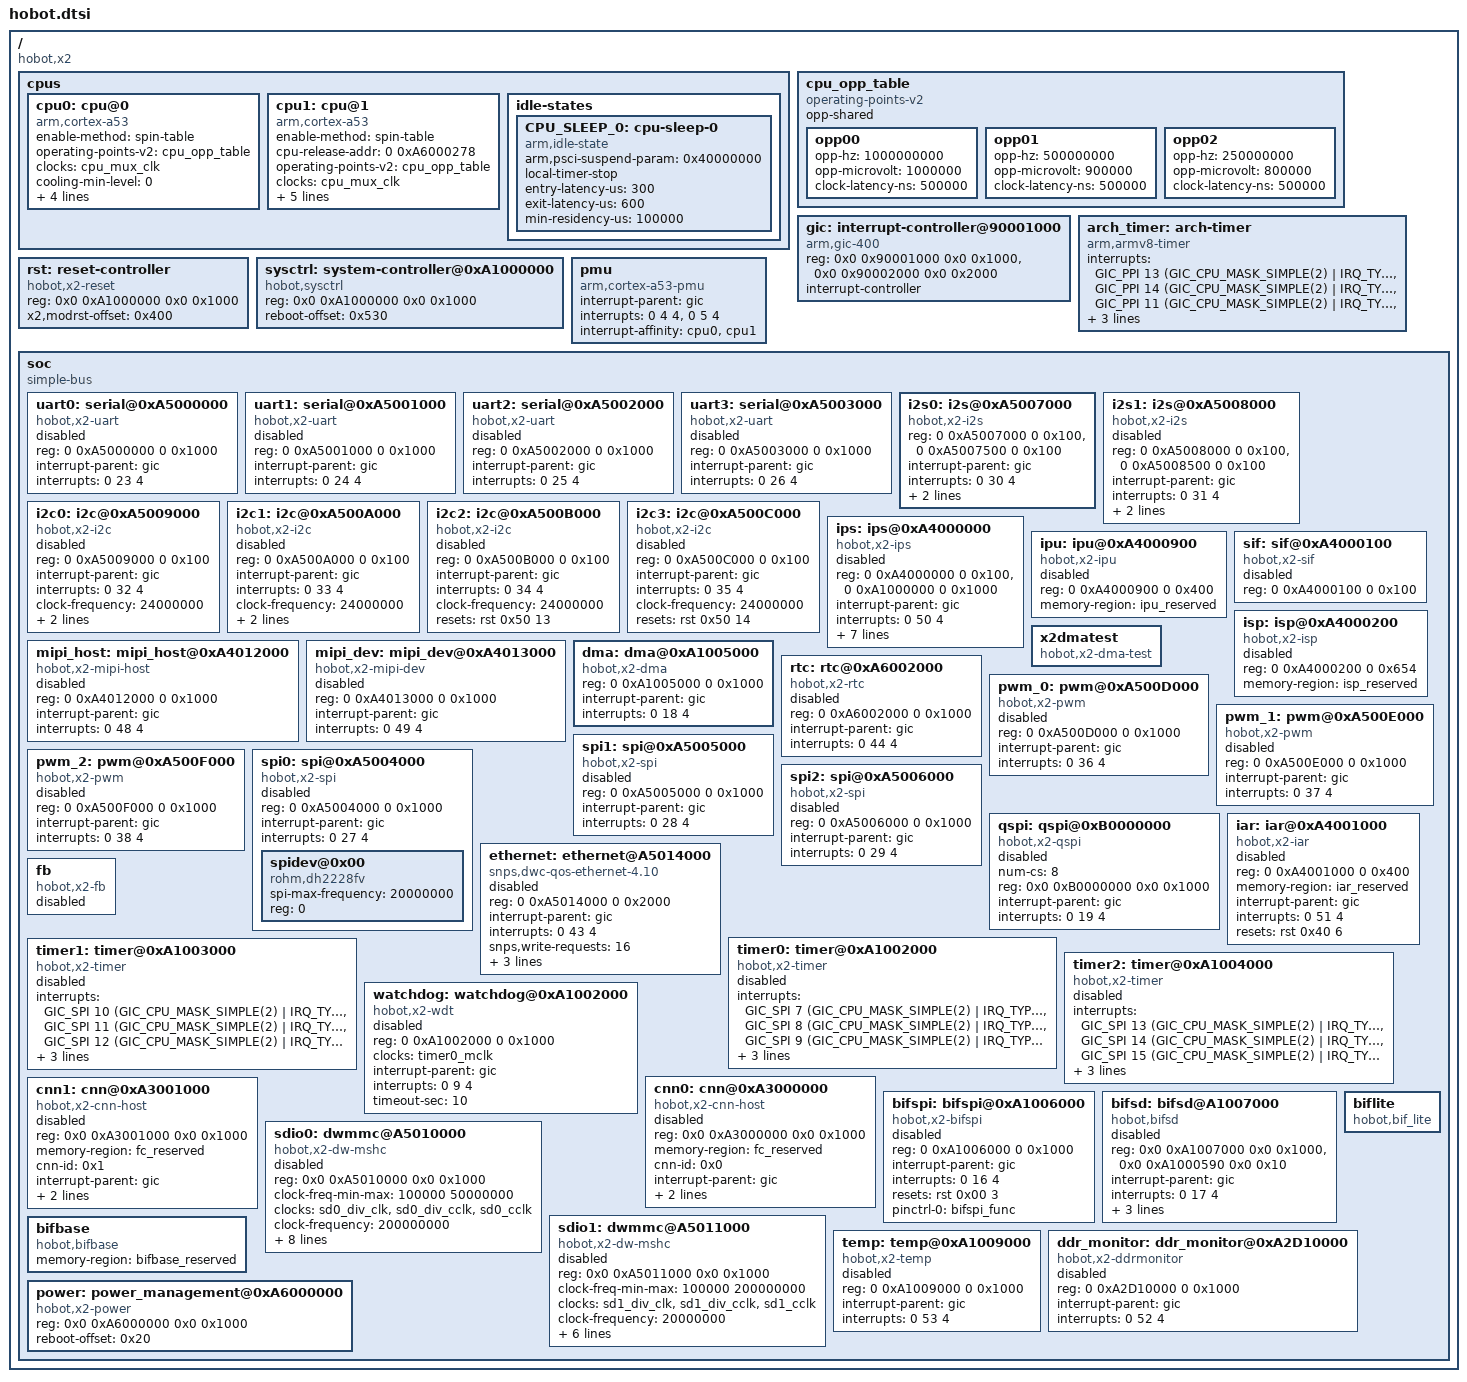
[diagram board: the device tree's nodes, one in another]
/*
 * dts file for Hobot X2 FPGA
 *
 * (C) Copyright 2018, Horizon, Inc.
 *
 *
 * This program is free software; you can redistribute it and/or
 * modify it under the terms of the GNU General Public License as
 * published by the Free Software Foundation; either version 2 of
 * the License, or (at your option) any later version.
 */

#include <dt-bindings/interrupt-controller/arm-gic.h>
#include <dt-bindings/interrupt-controller/irq.h>

 / {
	compatible = "hobot,x2";
	#address-cells = <2>;
	#size-cells = <2>;

	cpus {
		#address-cells = <1>;
		#size-cells = <0>;

		cpu0: cpu@0 {
			compatible = "arm,cortex-a53", "arm,armv8";
			device_type = "cpu";
			enable-method = "spin-table";
			operating-points-v2 = <&cpu_opp_table>;
			clocks = <&cpu_mux_clk>;
			#cooling-cells = <2>;
			cooling-min-level = <0>;
			cooling-max-level = <2>;
			dynamic-power-coefficient = <120>;
			reg = <0x0>;
			cpu-idle-states = <&CPU_SLEEP_0>;
		};

		cpu1: cpu@1 {
			compatible = "arm,cortex-a53", "arm,armv8";
			device_type = "cpu";
			enable-method = "spin-table";
			cpu-release-addr = <0 0xA6000278>;
			operating-points-v2 = <&cpu_opp_table>;
			clocks = <&cpu_mux_clk>;
			#cooling-cells = <2>;
			cooling-min-level = <0>;
			cooling-max-level = <2>;
			dynamic-power-coefficient = <120>;
			reg = <0x1>;
			cpu-idle-states = <&CPU_SLEEP_0>;
		};

		/*TODO: maybe need to change */
		idle-states {
			/*entry-method = "arm,psci";*/

			CPU_SLEEP_0: cpu-sleep-0 {
				compatible = "arm,idle-state";
				arm,psci-suspend-param = <0x40000000>;
				local-timer-stop;
				entry-latency-us = <300>;
				exit-latency-us = <600>;
				min-residency-us = <100000>;
			};
		};
	};

	/*TODO: maybe need to change or delete */
	cpu_opp_table: cpu_opp_table {
		compatible = "operating-points-v2";
		opp-shared;
		opp00 {
			opp-hz = /bits/ 64 <1000000000>;
			opp-microvolt = <1000000>;
			clock-latency-ns = <500000>;
		};
		opp01 {
			opp-hz = /bits/ 64 <500000000>;
			opp-microvolt = <900000>;
			clock-latency-ns = <500000>;
		};
		opp02 {
			opp-hz = /bits/ 64 <250000000>;
			opp-microvolt = <800000>;
			clock-latency-ns = <500000>;
		};
	};

/*
	psci {
		compatible = "arm,psci-0.2";
		method = "smc";
	};
*/

	gic: interrupt-controller@90001000 {
		compatible = "arm,gic-400", "arm,cortex-a53-gic";
		#interrupt-cells = <3>;
		reg = <0x0 0x90001000 0x0 0x1000>,		/* GICD */
			  <0x0 0x90002000 0x0 0x2000>;		/* GICC */
		interrupt-controller;
	};

	arch_timer: arch-timer{
		compatible = "arm,armv8-timer";
		interrupts = <GIC_PPI 13 (GIC_CPU_MASK_SIMPLE(2)
					 | IRQ_TYPE_LEVEL_LOW)>,
					 <GIC_PPI 14 (GIC_CPU_MASK_SIMPLE(2)
					 | IRQ_TYPE_LEVEL_LOW)>,
					 <GIC_PPI 11 (GIC_CPU_MASK_SIMPLE(2)
					 | IRQ_TYPE_LEVEL_LOW)>,
					 <GIC_PPI 10 (GIC_CPU_MASK_SIMPLE(2)
					 | IRQ_TYPE_LEVEL_LOW)>;
		interrupt-parent = <&gic>;
		clock-frequency = <20000000>;
	};

	rst: reset-controller {
		compatible = "hobot,x2-reset";
		#reset-cells = <2>;
		reg = <0x0 0xA1000000 0x0 0x1000>;
		x2,modrst-offset = <0x400>;
	};

	sysctrl: system-controller@0xA1000000 {
		compatible = "hobot,sysctrl";
		reg = <0x0 0xA1000000 0x0 0x1000>;
		reboot-offset = <0x530>;
	};

	pmu {
		compatible = "arm,cortex-a53-pmu", "arm,armv8-pmuv3";
		interrupt-parent = <&gic>;
		interrupts = <0 4 4>, <0 5 4>;
		interrupt-affinity = <&cpu0>,<&cpu1>;
	};

	soc {
		compatible = "simple-bus";
		#address-cells = <2>;
		#size-cells = <2>;
		ranges;

		uart0: serial@0xA5000000 {
			compatible = "hobot,x2-uart";
			reg = <0 0xA5000000 0 0x1000>;
			interrupt-parent = <&gic>;
			interrupts = <0 23 4>;
			status = "disabled";
		};

		uart1: serial@0xA5001000 {
			compatible = "hobot,x2-uart";
			reg = <0 0xA5001000 0 0x1000>;
			interrupt-parent = <&gic>;
			interrupts = <0 24 4>;
			status = "disabled";
		};

		uart2: serial@0xA5002000 {
			compatible = "hobot,x2-uart";
			reg = <0 0xA5002000 0 0x1000>;
			interrupt-parent = <&gic>;
			interrupts = <0 25 4>;
			status = "disabled";
		};

		uart3: serial@0xA5003000 {
			compatible = "hobot,x2-uart";
			reg = <0 0xA5003000 0 0x1000>;
			interrupt-parent = <&gic>;
			interrupts = <0 26 4>;
			status = "disabled";
		};

		i2s0: i2s@0xA5007000 {
			compatible = "hobot,x2-i2s";
			reg = <0 0xA5007000 0 0x100>,
				  <0 0xA5007500 0 0x100>;
			interrupt-parent = <&gic>;
			interrupts = <0 30 4>;
			resets = <&rst 0x50 18>;
			reset-names = "i2s";
			pinctrl-names = "default";
			pinctrl-0 = <&i2s0_func>;
		};

		i2s1: i2s@0xA5008000 {
			compatible = "hobot,x2-i2s";
			reg = <0 0xA5008000 0 0x100>,
				  <0 0xA5008500 0 0x100>;
			interrupt-parent = <&gic>;
			interrupts = <0 31 4>;
			resets = <&rst 0x50 19>;
			reset-names = "i2s";
			pinctrl-names = "default";
			pinctrl-0 = <&i2s1_func>;
			status = "disabled";
		};

		i2c0: i2c@0xA5009000 {
			compatible = "hobot,x2-i2c";
			reg = <0 0xA5009000 0 0x100>;
			interrupt-parent = <&gic>;
			interrupts = <0 32 4>;
			clock-frequency = <24000000>;
			resets = <&rst 0x50 11>;
			reset-names = "i2c0";
			status = "disabled";
			pinctrl-names = "default";
			pinctrl-0 = <&i2c0_func>;
		};

		i2c1: i2c@0xA500A000 {
			compatible = "hobot,x2-i2c";
			reg = <0 0xA500A000 0 0x100>;
			interrupt-parent = <&gic>;
			interrupts = <0 33 4>;
			clock-frequency = <24000000>;
			resets = <&rst 0x50 12>;
			reset-names = "i2c1";
			status = "disabled";
			pinctrl-names = "default";
			pinctrl-0 = <&i2c1_func>;
		};

		i2c2: i2c@0xA500B000 {
			compatible = "hobot,x2-i2c";
			reg = <0 0xA500B000 0 0x100>;
			interrupt-parent = <&gic>;
			interrupts = <0 34 4>;
			clock-frequency = <24000000>;
			resets = <&rst 0x50 13>;
			reset-names = "i2c2";
			status = "disabled";
		};

		i2c3: i2c@0xA500C000 {
			compatible = "hobot,x2-i2c";
			reg = <0 0xA500C000 0 0x100>;
			interrupt-parent = <&gic>;
			interrupts = <0 35 4>;
			clock-frequency = <24000000>;
			resets = <&rst 0x50 14>;
			reset-names = "i2c3";
			status = "disabled";
		};

		ips: ips@0xA4000000 {
			compatible = "hobot,x2-ips";
			reg = <0 0xA4000000 0 0x100>,
				  <0 0xA1000000 0  0x1000>;
			interrupt-parent = <&gic>;
			interrupts = <0 50 4>;
			status = "disabled";
			resets = <&rst 0x40 0>, <&rst 0x40 1>, <&rst 0x40 2>, <&rst 0x40 3>, <&rst 0x40 4>, <&rst 0x40 5>;
			reset-names = "mipi_ipi", "mipi_cfg", "sif", "ipu", "dvp", "bt";
			clocks = <&vio_pllmux_clk>, <&mipi_ipi_1stdiv_clk>,
				<&viopll_clk>, <&vio_div_aclk>,<&sif_div_mclk>,
				<&mipi_cfg_2nddiv_clk>,<&pym_div_mclk>,
				<&mipi_phy_ref_2nddiv_clk>,
				<&sensor_2nddiv_clk>,
				<&mipi_ipi_2nddiv_clk>,<&iar_pix_div_clk>;
			clock-names = "vio_pllmux", "ipi_div1",
				"vio_pll", "vio_aclk", "sif_mclk",
				"mipi_cfg", "pym_mclk", "mipi_phy_ref",
				"sensor_mclk", "ipi_div2", "iar_pix";
		};

		ipu: ipu@0xA4000900 {
			compatible = "hobot,x2-ipu";
			reg = <0 0xA4000900 0 0x400>;
			memory-region = <&ipu_reserved>;
			status = "disabled";
		};

		sif: sif@0xA4000100 {
			compatible = "hobot,x2-sif";
			reg = <0 0xA4000100 0 0x100>;
			status = "disabled";
		};

		isp: isp@0xA4000200 {
			compatible = "hobot,x2-isp";
			reg = <0 0xA4000200 0 0x654>;
			memory-region = <&isp_reserved>;
			status = "disabled";
		};

		mipi_host: mipi_host@0xA4012000 {
			compatible = "hobot,x2-mipi-host";
			reg = <0 0xA4012000 0 0x1000>;
			interrupt-parent = <&gic>;
			interrupts = <0 48 4>;
			status = "disabled";
		};

		mipi_dev: mipi_dev@0xA4013000 {
			compatible = "hobot,x2-mipi-dev";
			reg = <0 0xA4013000 0 0x1000>;
			interrupt-parent = <&gic>;
			interrupts = <0 49 4>;
			status = "disabled";
		};

		dma: dma@0xA1005000 {
			compatible = "hobot,x2-dma";
			reg = <0 0xA1005000 0 0x1000>;
			interrupt-parent = <&gic>;
			interrupts = <0 18 4>;
		};

		x2dmatest: x2dmatest {
			compatible = "hobot,x2-dma-test";
		};

		rtc: rtc@0xA6002000 {
			compatible = "hobot,x2-rtc";
			reg = <0 0xA6002000 0 0x1000>;
			interrupt-parent = <&gic>;
			interrupts = <0 44 4>;
			status = "disabled";
		};

		pwm_0: pwm@0xA500D000 {
			compatible = "hobot,x2-pwm";
			reg = <0 0xA500D000 0 0x1000>;
			interrupt-parent = <&gic>;
			interrupts = <0 36 4>;
			status = "disabled";
		};

		pwm_1: pwm@0xA500E000 {
			compatible = "hobot,x2-pwm";
			reg = <0 0xA500E000 0 0x1000>;
			interrupt-parent = <&gic>;
			interrupts = <0 37 4>;
			status = "disabled";
		};

		pwm_2: pwm@0xA500F000 {
			compatible = "hobot,x2-pwm";
			reg = <0 0xA500F000 0 0x1000>;
			interrupt-parent = <&gic>;
			interrupts = <0 38 4>;
			status = "disabled";
		};

		spi0: spi@0xA5004000 {
			compatible = "hobot,x2-spi";
			reg = <0 0xA5004000 0 0x1000>;
			interrupt-parent = <&gic>;
			interrupts = <0 27 4>;
			status = "disabled";
			#address-cells = <1>;
			#size-cells = <0>;
			spidev@0x00 {
				compatible = "rohm,dh2228fv";
				spi-max-frequency = <20000000>;
				reg = <0>;
			};
		};

		spi1: spi@0xA5005000 {
			compatible = "hobot,x2-spi";
			reg = <0 0xA5005000 0 0x1000>;
			interrupt-parent = <&gic>;
			interrupts = <0 28 4>;
			status = "disabled";
			#address-cells = <1>;
			#size-cells = <0>;
		};

		spi2: spi@0xA5006000 {
			compatible = "hobot,x2-spi";
			reg = <0 0xA5006000 0 0x1000>;
			interrupt-parent = <&gic>;
			interrupts = <0 29 4>;
			status = "disabled";
			#address-cells = <1>;
			#size-cells = <0>;
		};

		qspi: qspi@0xB0000000 {
			compatible = "hobot,x2-qspi";
			status = "disabled";
			num-cs = <8>;
			reg = <0x0 0xB0000000 0x0 0x1000>;
			interrupt-parent = <&gic>;
			interrupts = <0 19 4>;
		};

		ethernet: ethernet@A5014000 {
			compatible = "snps,dwc-qos-ethernet-4.10";
			reg = <0 0xA5014000 0 0x2000>;
			interrupt-parent = <&gic>;
			interrupts = <0 43 4>;

			snps,write-requests = <16>;
			snps,read-requests = <32>;
			snps,txpbl = <32>;
			snps,rxpbl = <16>;

			status = "disabled";
		};

		iar: iar@0xA4001000 {
			compatible = "hobot,x2-iar";
			reg = <0 0xA4001000 0 0x400>;
			memory-region = <&iar_reserved>;
			interrupt-parent = <&gic>;
			interrupts = <0 51 4>;
			resets = <&rst 0x40 6>;
			reset-names = "iar";
			status = "disabled";
		};

		fb: fb {
			compatible = "hobot,x2-fb";
			status = "enabled";
		};

		timer0: timer@0xA1002000 {
			compatible = "hobot,x2-timer";
			status = "disabled";
			interrupts = <GIC_SPI 7 (GIC_CPU_MASK_SIMPLE(2)
						 | IRQ_TYPE_LEVEL_HIGH)>,
						 <GIC_SPI 8 (GIC_CPU_MASK_SIMPLE(2)
						 | IRQ_TYPE_LEVEL_HIGH)>,
						 <GIC_SPI 9 (GIC_CPU_MASK_SIMPLE(2)
						 | IRQ_TYPE_LEVEL_HIGH)>;
			interrupt-parent = <&gic>;
			reg = <0x0 0xA1002000 0x0 0x1000>;
			timer-freq = <20000000>;
		};

		timer1: timer@0xA1003000 {
			compatible = "hobot,x2-timer";
			status = "disabled";
			interrupts = <GIC_SPI 10 (GIC_CPU_MASK_SIMPLE(2)
						 | IRQ_TYPE_LEVEL_HIGH)>,
						 <GIC_SPI 11 (GIC_CPU_MASK_SIMPLE(2)
						 | IRQ_TYPE_LEVEL_HIGH)>,
						 <GIC_SPI 12 (GIC_CPU_MASK_SIMPLE(2)
						 | IRQ_TYPE_LEVEL_HIGH)>;
			interrupt-parent = <&gic>;
			reg = <0x0 0xA1003000 0x0 0x1000>;
			timer-freq = <20000000>;
		};

		timer2: timer@0xA1004000 {
			compatible = "hobot,x2-timer";
			status = "disabled";
			interrupts = <GIC_SPI 13 (GIC_CPU_MASK_SIMPLE(2)
						 | IRQ_TYPE_LEVEL_HIGH)>,
						 <GIC_SPI 14 (GIC_CPU_MASK_SIMPLE(2)
						 | IRQ_TYPE_LEVEL_HIGH)>,
						 <GIC_SPI 15 (GIC_CPU_MASK_SIMPLE(2)
						 | IRQ_TYPE_LEVEL_HIGH)>;
			interrupt-parent = <&gic>;
			reg = <0x0 0xA1004000 0x0 0x1000>;
			timer-freq = <20000000>;
		};

		watchdog: watchdog@0xA1002000 {
			compatible = "hobot,x2-wdt";
			reg = <0 0xA1002000 0 0x1000>;
			clocks = <&timer0_mclk>;
			clock-names = "watchdog_mclk";
			interrupt-parent = <&gic>;
			interrupts = <0 9 4>;
			timeout-sec = <10>;
			status = "disabled";
		};

		cnn0: cnn@0xA3000000 {
			compatible = "hobot,x2-cnn-host";
			reg = <0x0 0xA3000000 0x0 0x1000>;
			memory-region = <&fc_reserved>;
			cnn-id = <0x0>;
			interrupt-parent = <&gic>;
			interrupts = <0 46 4>;
			resets = <&rst 0x20 0 >;
			reset-names = "cnn0_rst";
			status = "disabled";
		};

		cnn1: cnn@0xA3001000 {
			compatible = "hobot,x2-cnn-host";
			reg = <0x0 0xA3001000 0x0 0x1000>;
			memory-region = <&fc_reserved>;
			cnn-id = <0x1>;
			interrupt-parent = <&gic>;
			interrupts = <0 47 4>;
			resets = <&rst 0x20 1 >;
			reset-names = "cnn1_rst";
			status = "disabled";
		};
		bifspi: bifspi@0xA1006000 {
			compatible = "hobot,x2-bifspi";
			reg = <0 0xA1006000 0 0x1000>;
			interrupt-parent = <&gic>;
			interrupts = <0 16 4>;
			status = "disabled";
			resets = <&rst 0x00 3>;
			reset-names = "bifspi";
			pinctrl-names = "default";
			pinctrl-0 = <&bifspi_func>;
		};
		bifsd: bifsd@A1007000 {
			compatible = "hobot,bifsd";
			reg = <0x0 0xA1007000 0x0 0x1000>,
				  <0x0 0xA1000590 0x0 0x10>;
			interrupt-parent = <&gic>;
			interrupts = <0 17 4>;
			memory-region = <&bifsd_reserved>;
			status = "disabled";
			resets = <&rst 0x00 5>;
			reset-names = "bifsd";
			pinctrl-names = "default";
			pinctrl-0 = <&bifsd_func>;
		};
		sdio0: dwmmc@A5010000 {
			compatible = "hobot,x2-dw-mshc";
			reg = <0x0 0xA5010000 0x0 0x1000>;
			clock-freq-min-max = <100000 50000000>;
			clocks = <&sd0_div_clk>, <&sd0_div_cclk>,<&sd0_cclk>;
			clock-names = "biu","ciu","gate_cclk";
			clock-frequency = <200000000>;
			fifo-depth = <0x100>;
			fifo-mode = <0>;
			no-sd;
			no-sdio;
			interrupt-parent = <&gic>;
			interrupts = <0 39 4>;
			status = "disabled";
			reset = <&rst 0x50 15>;
			reset-names = "reset";
			pinctrl-names = "default";
			pinctrl-0 = <&sdio0_func>;
		};
		sdio1: dwmmc@A5011000 {
			compatible = "hobot,x2-dw-mshc";
			reg = <0x0 0xA5011000 0x0 0x1000>;
			clock-freq-min-max = <100000 200000000>;
			clocks = <&sd1_div_clk>, <&sd1_div_cclk>,<&sd1_cclk>;
			clock-names = "biu","ciu","gate_cclk";
			clock-frequency = <20000000>;
			fifo-depth = <0x100>;
			fifo-mode = <0>;
			interrupt-parent = <&gic>;
			interrupts = <0 40 4>;
			status = "disabled";
			reset = <&rst 0x50 16>;
			reset-names = "reset";
			pinctrl-names = "default";
			pinctrl-0 = <&sdio1_func>;
		};
		bifbase: bifbase {
			compatible = "hobot,bifbase";
			memory-region = <&bifbase_reserved>;
		};
		biflite: biflite {
			compatible = "hobot,bif_lite";
		};
		temp: temp@0xA1009000 {
			compatible = "hobot,x2-temp";
			reg = <0 0xA1009000 0 0x1000>;
			interrupt-parent = <&gic>;
			interrupts = <0 53 4>;
			status = "disabled";
		};

		ddr_monitor: ddr_monitor@0xA2D10000 {
			compatible = "hobot,x2-ddrmonitor";
			reg = <0 0xA2D10000 0 0x1000>;
			interrupt-parent = <&gic>;
			interrupts = <0 52 4>;
			status = "disabled";
		};

		power: power_management@0xA6000000 {
			compatible = "hobot,x2-power";
			reg = <0x0 0xA6000000 0x0 0x1000>;
			reboot-offset = <0x20>;
		};

	};
};

